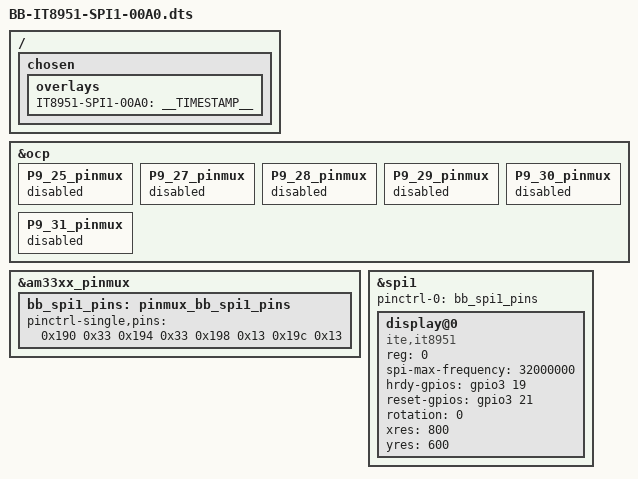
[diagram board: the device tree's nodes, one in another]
/*
 * Copyright (C) 2013 CircuitCo
 * Copyright (C) 2018 Drew Fustini <drew@beagleboard.org>
 * Copyright (C) 2019 Mark A. Yoder <mark.a.yoder@beagleboard.org>
 *
 * Waveshare Eink display on SPI1 bus using tinydrm it8951 driver
 *
 * LICENSE:
 * --------
 * This program is free software; you can redistribute it and/or modify
 * it under the terms of the GNU General Public License version 2 as
 * published by the Free Software Foundation.
 *
 * DOCUMENTATION:
 * --------------
 *
 *   P9.20 <--> reset
 *   P9.19 <--> hrdy
 *   P9.17 <--> cs
 *   P9.18 <--> mosi
 *   P9.21 <--> miso
 *   P9.22 <--> clk
 *
 */

#include <dt-bindings/gpio/gpio.h>
#include <dt-bindings/pinctrl/am33xx.h>
#include <dt-bindings/board/am335x-bbw-bbb-base.h>

/dts-v1/;
/plugin/;

/ {
	/*
	 * Helper to show loaded overlays under: /proc/device-tree/chosen/overlays/
	 */
	fragment@0 {
		target-path="/";
		__overlay__ {

			chosen {
				overlays {
					IT8951-SPI1-00A0 = __TIMESTAMP__;
				};
			};
		};
	};

	/*
	 * Free up the pins used by the cape from the pinmux helpers.
	 */

	fragment@1 {
		target = <&ocp>;
		__overlay__ {
			P9_25_pinmux { status = "disabled"; };	/* reset */
			P9_27_pinmux { status = "disabled"; };	/* hrdy */
			P9_28_pinmux { status = "disabled"; };	/* spi1_cs0 */
			P9_29_pinmux { status = "disabled"; };	/* spi1_d0 */
			P9_30_pinmux { status = "disabled"; };	/* spi1_d1 */
			P9_31_pinmux { status = "disabled"; };	/* spi1_sclk */
		};
	};

	fragment@2 {
		target = <&am33xx_pinmux>;
		__overlay__ {
			/* default state has all gpios released and mode set to uart1 */
			/* See page 1446 of am35xx TRM */
			bb_spi1_pins: pinmux_bb_spi1_pins {
				pinctrl-single,pins = <
					0x190 0x33	/* mcasp0_aclkx.spi1_sclk,  INPUT_PULLUP | MODE3 */
					0x194 0x33	/* mcasp0_fsx.spi1_d0,      INPUT_PULLUP | MODE3 */
					0x198 0x13	/* mcasp0_axr0.spi1_d1,    OUTPUT_PULLUP | MODE3 */
					0x19c 0x13	/* mcasp0_ahclkr.spi1_cs0, OUTPUT_PULLUP | MODE3 */
					// 0x164 0x12	/* eCAP0_in_PWM0_out.spi1_cs1 OUTPUT_PULLUP | MODE2 */
				>;
			};

		};
	};

	fragment@3 {
		target = <&spi1>;
		__overlay__ {
			#address-cells = <1>;
			#size-cells = <0>;

			status = "okay";
			pinctrl-names = "default";
			pinctrl-0 = <&bb_spi1_pins>;

			display@0{
				status = "okay";
				compatible = "ite,it8951";
				reg = <0>;
				spi-max-frequency = <32000000>;
				hrdy-gpios    = <&gpio3 19 0>;   // hrdy    P9.27 gpio3[19]
				reset-gpios = <&gpio3 21 0>;   // reset P9.25 gpio3[21]

				rotation = <0>;
				xres = <800>;
				yres = <600>;
			};
		};
	};
};
